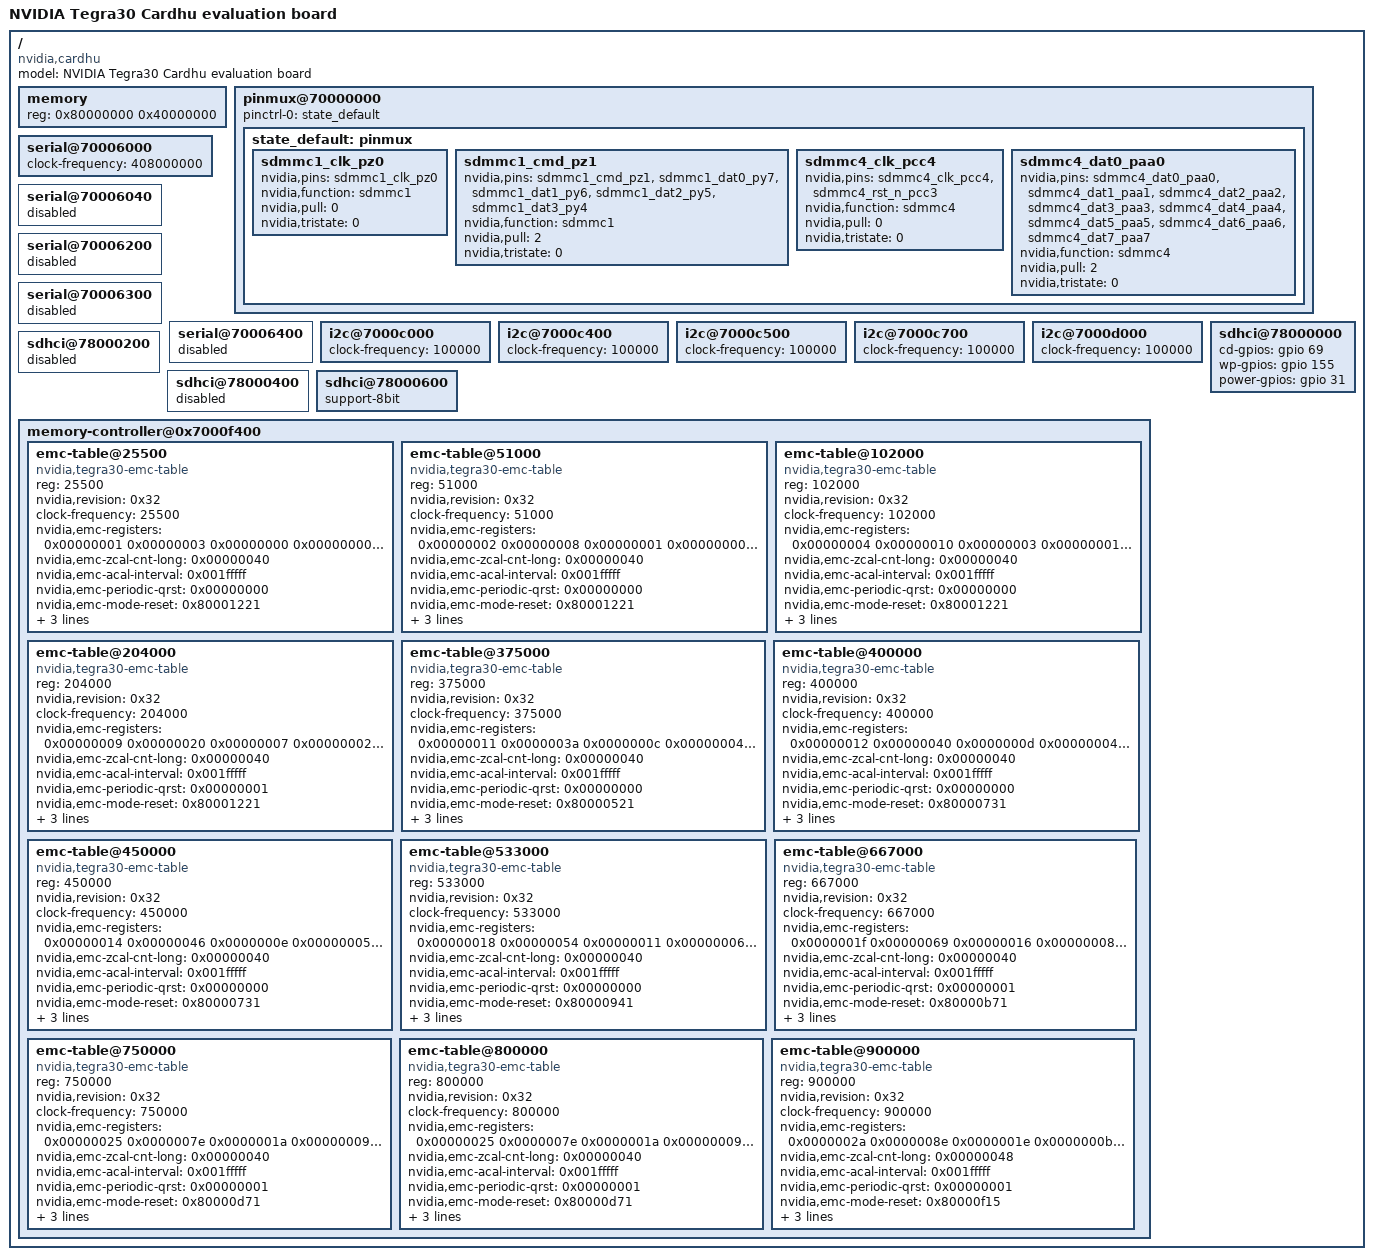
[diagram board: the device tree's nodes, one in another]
/dts-v1/;

/include/ "tegra30.dtsi"

/ {
	model = "NVIDIA Tegra30 Cardhu evaluation board";
	compatible = "nvidia,cardhu", "nvidia,tegra30";

	memory {
		reg = < 0x80000000 0x40000000 >;
	};

	pinmux@70000000 {
		pinctrl-names = "default";
		pinctrl-0 = <&state_default>;

		state_default: pinmux {
			sdmmc1_clk_pz0 {
				nvidia,pins = "sdmmc1_clk_pz0";
				nvidia,function = "sdmmc1";
				nvidia,pull = <0>;
				nvidia,tristate = <0>;
			};
			sdmmc1_cmd_pz1 {
				nvidia,pins =	"sdmmc1_cmd_pz1",
						"sdmmc1_dat0_py7",
						"sdmmc1_dat1_py6",
						"sdmmc1_dat2_py5",
						"sdmmc1_dat3_py4";
				nvidia,function = "sdmmc1";
				nvidia,pull = <2>;
				nvidia,tristate = <0>;
			};
			sdmmc4_clk_pcc4 {
				nvidia,pins =	"sdmmc4_clk_pcc4",
						"sdmmc4_rst_n_pcc3";
				nvidia,function = "sdmmc4";
				nvidia,pull = <0>;
				nvidia,tristate = <0>;
			};
			sdmmc4_dat0_paa0 {
				nvidia,pins =	"sdmmc4_dat0_paa0",
						"sdmmc4_dat1_paa1",
						"sdmmc4_dat2_paa2",
						"sdmmc4_dat3_paa3",
						"sdmmc4_dat4_paa4",
						"sdmmc4_dat5_paa5",
						"sdmmc4_dat6_paa6",
						"sdmmc4_dat7_paa7";
				nvidia,function = "sdmmc4";
				nvidia,pull = <2>;
				nvidia,tristate = <0>;
			};
		};
	};

	serial@70006000 {
		clock-frequency = < 408000000 >;
	};

	serial@70006040 {
		status = "disable";
	};

	serial@70006200 {
		status = "disable";
	};

	serial@70006300 {
		status = "disable";
	};

	serial@70006400 {
		status = "disable";
	};

	i2c@7000c000 {
		clock-frequency = <100000>;
	};

	i2c@7000c400 {
		clock-frequency = <100000>;
	};

	i2c@7000c500 {
		clock-frequency = <100000>;
	};

	i2c@7000c700 {
		clock-frequency = <100000>;
	};

	i2c@7000d000 {
		clock-frequency = <100000>;
	};

	sdhci@78000000 {
		cd-gpios = <&gpio 69 0>; /* gpio PI5 */
		wp-gpios = <&gpio 155 0>; /* gpio PT3 */
		power-gpios = <&gpio 31 0>; /* gpio PD7 */
	};

	sdhci@78000200 {
		status = "disable";
	};

	sdhci@78000400 {
		status = "disable";
	};

	sdhci@78000600 {
		support-8bit;
	};

	memory-controller@0x7000f400 {
		emc-table@25500 {
			compatible = "nvidia,tegra30-emc-table";
			reg = <25500>;
			nvidia,revision = <0x32>;
			clock-frequency = <25500>;
			nvidia,emc-registers = <0x00000001 0x00000003
					0x00000000 0x00000000 0x00000002 0x0000000a 0x00000003 0x0000000b 0x00000000
					0x00000000 0x00000003 0x00000001 0x00000000 0x00000005 0x00000005 0x00000004
					0x00000007 0x0000000c 0x000000bd 0x00000000 0x0000002f 0x00000002 0x00000002
					0x00000001 0x00000000 0x00000007 0x0000000f 0x00000005 0x00000005 0x00000004
					0x00000001 0x00000000 0x00000004 0x00000005 0x000000c3 0x00000000 0x00000004
					0x00000000 0x00000000 0x00006288 0x007800a4 0x00008000 0x00080000 0x00080000
					0x00080000 0x00080000 0x00080000 0x00080000 0x00080000 0x00080000 0x00000000
					0x00000000 0x00000000 0x00000000 0x00000000 0x00000000 0x00000000 0x00000000
					0x00000000 0x00000000 0x00000000 0x00000000 0x00000000 0x00000000 0x00000000
					0x00000000 0x00080000 0x00080000 0x00080000 0x00080000 0x000002a0 0x0800211c
					0x00000000 0x77ffc084 0x01f1f108 0x05057404 0x54000007 0x08000168 0x08000000
					0x00000802 0x00000000 0x00000040 0x000c000c 0xa0f10000 0x00000000 0x00000000
					0x80000280 0x00020001 0xc0000010 0x00000001 0x00000001 0x00000002 0x00000000
					0x00000001 0x00000001 0x00000002 0x00000008 0x00000002 0x00000001 0x00000002
					0x00000006 0x06020102 0x000a0402 0x74430303 0x001f0000 0xd8000000 0xff00ff00>;
			nvidia,emc-zcal-cnt-long = <0x00000040>;
			nvidia,emc-acal-interval = <0x001fffff>;
			nvidia,emc-periodic-qrst = <0x00000000>;
			nvidia,emc-mode-reset = <0x80001221>;
			nvidia,emc-mode-1 = <0x80100003>;
			nvidia,emc-mode-2 = <0x80200008>;
			nvidia,emc-dsr = <0x00000001>;
		};

		emc-table@51000 {
			compatible = "nvidia,tegra30-emc-table";
			reg = <51000>;
			nvidia,revision = <0x32>;
			clock-frequency = <51000>;
			nvidia,emc-registers = < 0x00000002 0x00000008
					0x00000001 0x00000000 0x00000002 0x0000000a 0x00000003 0x0000000b 0x00000000
					0x00000000 0x00000003 0x00000001 0x00000000 0x00000005 0x00000005 0x00000004
					0x00000007 0x0000000c 0x00000181 0x00000000 0x00000060 0x00000002 0x00000002
					0x00000001 0x00000000 0x00000007 0x0000000f 0x00000009 0x00000009 0x00000004
					0x00000002 0x00000000 0x00000004 0x00000005 0x0000018e 0x00000000 0x00000004
					0x00000000 0x00000000 0x00006288 0x007800a4 0x00008000 0x00080000 0x00080000
					0x00080000 0x00080000 0x00080000 0x00080000 0x00080000 0x00080000 0x00000000
					0x00000000 0x00000000 0x00000000 0x00000000 0x00000000 0x00000000 0x00000000
					0x00000000 0x00000000 0x00000000 0x00000000 0x00000000 0x00000000 0x00000000
					0x00000000 0x00080000 0x00080000 0x00080000 0x00080000 0x000002a0 0x0800211c
					0x00000000 0x77ffc084 0x01f1f108 0x05057404 0x54000007 0x08000168 0x08000000
					0x00000802 0x00000000 0x00000040 0x000c000c 0xa0f10000 0x00000000 0x00000000
					0x8000040b 0x00000001 0xc0000010 0x00000001 0x00000001 0x00000002 0x00000000
					0x00000001 0x00000001 0x00000002 0x00000008 0x00000002 0x00000001 0x00000002
					0x00000006 0x06020102 0x000a0402 0x73430303 0x001f0000 0xd8000000 0xff00ff00>;
			nvidia,emc-zcal-cnt-long = <0x00000040>;
			nvidia,emc-acal-interval = <0x001fffff>;
			nvidia,emc-periodic-qrst = <0x00000000>;
			nvidia,emc-mode-reset = <0x80001221>;
			nvidia,emc-mode-1 = <0x80100003>;
			nvidia,emc-mode-2 = <0x80200008>;
			nvidia,emc-dsr = <0x00000001>;
		};

		emc-table@102000 {
			compatible = "nvidia,tegra30-emc-table";
			reg = <102000>;
			nvidia,revision = <0x32>;
			clock-frequency = <102000>;
			nvidia,emc-registers = <0x00000004 0x00000010
					0x00000003 0x00000001 0x00000002 0x0000000a 0x00000003 0x0000000b 0x00000001
					0x00000001 0x00000003 0x00000001 0x00000000 0x00000005 0x00000005 0x00000004
					0x00000007 0x0000000c 0x00000303 0x00000000 0x000000c0 0x00000002 0x00000002
					0x00000001 0x00000000 0x00000007 0x0000000f 0x00000012 0x00000012 0x00000004
					0x00000004 0x00000000 0x00000004 0x00000005 0x0000031c 0x00000000 0x00000004
					0x00000000 0x00000000 0x00006288 0x007800a4 0x00008000 0x00080000 0x00080000
					0x00080000 0x00080000 0x00080000 0x00080000 0x00080000 0x00080000 0x00000000
					0x00000000 0x00000000 0x00000000 0x00000000 0x00000000 0x00000000 0x00000000
					0x00000000 0x00000000 0x00000000 0x00000000 0x00000000 0x00000000 0x00000000
					0x00000000 0x00080000 0x00080000 0x00080000 0x00080000 0x000002a0 0x0800211c
					0x00000000 0x77ffc084 0x01f1f108 0x05057404 0x54000007 0x08000168 0x08000000
					0x00000802 0x00000000 0x00000040 0x000c000c 0xa0f10000 0x00000000 0x00000000
					0x80000713 0x00000001 0xc0000018 0x00000001 0x00000001 0x00000003 0x00000000
					0x00000001 0x00000001 0x00000002 0x00000008 0x00000002 0x00000001 0x00000002
					0x00000006 0x06020102 0x000a0403 0x72830504 0x001f0000 0xd8000000 0xff00ff00>;
			nvidia,emc-zcal-cnt-long = <0x00000040>;
			nvidia,emc-acal-interval = <0x001fffff>;
			nvidia,emc-periodic-qrst = <0x00000000>;
			nvidia,emc-mode-reset = <0x80001221>;
			nvidia,emc-mode-1 = <0x80100003>;
			nvidia,emc-mode-2 = <0x80200008>;
			nvidia,emc-dsr = <0x00000001>;
		};

		emc-table@204000 {
			compatible = "nvidia,tegra30-emc-table";
			reg = <204000>;
			nvidia,revision = <0x32>;
			clock-frequency = <204000>;
			nvidia,emc-registers = <0x00000009 0x00000020
					0x00000007 0x00000002 0x00000002 0x0000000a 0x00000005 0x0000000b 0x00000002
					0x00000002 0x00000003 0x00000001 0x00000000 0x00000005 0x00000005 0x00000004
					0x00000009 0x0000000b 0x00000607 0x00000000 0x00000181 0x00000002 0x00000002
					0x00000001 0x00000000 0x00000007 0x0000000f 0x00000023 0x00000023 0x00000004
					0x00000007 0x00000000 0x00000004 0x00000005 0x00000638 0x00000006 0x00000004
					0x00000000 0x00000000 0x00004288 0x004400a4 0x00008000 0x00080000 0x00080000
					0x00080000 0x00080000 0x00080000 0x00080000 0x00080000 0x00080000 0x00000000
					0x00000000 0x00000000 0x00000000 0x00000000 0x00000000 0x00000000 0x00000000
					0x00000000 0x00000000 0x00000000 0x00000000 0x00000000 0x00000000 0x00000000
					0x00000000 0x00080000 0x00080000 0x00080000 0x00080000 0x000002a0 0x0800211c
					0x00000000 0x77fff884 0x01f1f108 0x05057404 0x54000007 0x08000168 0x08000000
					0x00000802 0x00020000 0x00000100 0x000c000c 0xa0f10000 0x00000000 0x00000000
					0x80000d22 0x00000003 0xc0000025 0x00000001 0x00000001 0x00000005 0x00000002
					0x00000003 0x00000001 0x00000003 0x00000008 0x00000002 0x00000001 0x00000002
					0x00000006 0x06020102 0x000a0505 0x72440a06 0x001f0000 0xe8000000 0xff00ff00>;
			nvidia,emc-zcal-cnt-long = <0x00000040>;
			nvidia,emc-acal-interval = <0x001fffff>;
			nvidia,emc-periodic-qrst = <0x00000001>;
			nvidia,emc-mode-reset = <0x80001221>;
			nvidia,emc-mode-1 = <0x80100003>;
			nvidia,emc-mode-2 = <0x80200008>;
			nvidia,emc-dsr = <0x00000001>;
		};

		emc-table@375000 {
			compatible = "nvidia,tegra30-emc-table";
			reg = <375000>;
			nvidia,revision = <0x32>;
			clock-frequency = <375000>;
			nvidia,emc-registers = <0x00000011 0x0000003a
					0x0000000c 0x00000004 0x00000003 0x00000008 0x00000002 0x0000000a 0x00000004
					0x00000004 0x00000002 0x00000001 0x00000000 0x00000004 0x00000006 0x00000004
					0x00000008 0x0000000d 0x00000b2d 0x00000000 0x000002cb 0x00000008 0x00000008
					0x00000001 0x00000000 0x00000007 0x0000000f 0x00000040 0x00000200 0x00000009
					0x0000000c 0x00000000 0x00000004 0x00000005 0x00000b6d 0x00000000 0x00000006
					0x00000000 0x00000000 0x00007088 0x00200084 0x00008000 0x0003c000 0x0003c000
					0x0003c000 0x0003c000 0x0003c000 0x0003c000 0x0003c000 0x0003c000 0x00000000
					0x00000000 0x00000000 0x00000000 0x00000000 0x00000000 0x00000000 0x00000000
					0x00000000 0x00000000 0x00000000 0x00000000 0x00000000 0x00000000 0x00000000
					0x00000000 0x00040000 0x00040000 0x00040000 0x00040000 0x000002a0 0x0800013d
					0x00000000 0x77fff884 0x01f1f508 0x05057404 0x54000007 0x080001e8 0x08000021
					0x00000802 0x00020000 0x00000100 0x0184000c 0xa0f10000 0x00000000 0x00000000
					0x8000174b 0x00000005 0x80000044 0x00000001 0x00000002 0x00000009 0x00000005
					0x00000005 0x00000001 0x00000002 0x00000008 0x00000002 0x00000002 0x00000003
					0x00000006 0x06030202 0x000d0709 0x75c6110a 0x001f0000 0x58000000 0xff00ff88>;
			nvidia,emc-zcal-cnt-long = <0x00000040>;
			nvidia,emc-acal-interval = <0x001fffff>;
			nvidia,emc-periodic-qrst = <0x00000000>;
			nvidia,emc-mode-reset = <0x80000521>;
			nvidia,emc-mode-1 = <0x80100002>;
			nvidia,emc-mode-2 = <0x80200000>;
			nvidia,emc-dsr = <0x00000000>;
		};

		emc-table@400000 {
			compatible = "nvidia,tegra30-emc-table";
			reg = <400000>;
			nvidia,revision = <0x32>;
			clock-frequency = <400000>;
			nvidia,emc-registers = <0x00000012 0x00000040
					0x0000000d 0x00000004 0x00000002 0x00000009 0x00000002 0x0000000c 0x00000004
					0x00000004 0x00000002 0x00000001 0x00000000 0x00000005 0x00000007 0x00000005
					0x00000008 0x0000000e 0x00000c2e 0x00000000 0x0000030b 0x00000008 0x00000008
					0x00000001 0x00000000 0x00000008 0x00000011 0x00000046 0x00000200 0x0000000a
					0x0000000d 0x00000000 0x00000004 0x00000005 0x00000c6f 0x00000000 0x00000006
					0x00000000 0x00000000 0x00007088 0x001c0084 0x00008000 0x00034000 0x00034000
					0x00034000 0x00034000 0x00034000 0x00034000 0x00034000 0x00034000 0x00000000
					0x00000000 0x00000000 0x00000000 0x00000000 0x00000000 0x00000000 0x00000000
					0x00000000 0x00000000 0x00000000 0x00000000 0x00000000 0x00000000 0x00000000
					0x00000000 0x00040000 0x00040000 0x00040000 0x00040000 0x000002a0 0x0800013d
					0x00000000 0x77fff884 0x01f1f508 0x05057404 0x54000007 0x080001e8 0x08000021
					0x00000802 0x00020000 0x00000100 0x017f000c 0xa0f10000 0x00000000 0x00000000
					0x80001941 0x00000006 0x8000004a 0x00000001 0x00000002 0x0000000a 0x00000006
					0x00000006 0x00000001 0x00000002 0x00000009 0x00000002 0x00000002 0x00000003
					0x00000006 0x06030202 0x000e070a 0x7547130b 0x001f0000 0x58000000 0xff00ff88>;
			nvidia,emc-zcal-cnt-long = <0x00000040>;
			nvidia,emc-acal-interval = <0x001fffff>;
			nvidia,emc-periodic-qrst = <0x00000000>;
			nvidia,emc-mode-reset = <0x80000731>;
			nvidia,emc-mode-1 = <0x80100002>;
			nvidia,emc-mode-2 = <0x80200008>;
			nvidia,emc-dsr = <0x00000000>;
		};

		emc-table@450000 {
			compatible = "nvidia,tegra30-emc-table";
			reg = <450000>;
			nvidia,revision = <0x32>;
			clock-frequency = <450000>;
			nvidia,emc-registers = <0x00000014 0x00000046
					0x0000000e 0x00000005 0x00000003 0x00000009 0x00000002 0x0000000c 0x00000005
					0x00000005 0x00000002 0x00000001 0x00000000 0x00000005 0x00000007 0x00000005
					0x0000000a 0x0000000e 0x00000d76 0x00000000 0x0000035d 0x00000001 0x00000009
					0x00000001 0x00000000 0x00000009 0x00000011 0x0000004d 0x00000200 0x00000004
					0x0000000e 0x00000000 0x00000004 0x00000005 0x00000db6 0x00000000 0x00000006
					0x00000000 0x00000000 0x00007088 0x00180084 0x00008000 0x00022000 0x00022000
					0x00022000 0x00022000 0x00022000 0x00022000 0x00022000 0x00022000 0x00000000
					0x00000000 0x00000000 0x00000000 0x00000000 0x00000000 0x00000000 0x00000000
					0x00000000 0x00000000 0x00000000 0x00000000 0x00000000 0x00000000 0x00000000
					0x00000000 0x00030000 0x00030000 0x00030000 0x00030000 0x000002a0 0x0800013d
					0x00000000 0x77fff884 0x01f1f508 0x05057404 0x54000007 0x080001e8 0x08000021
					0x00000802 0x00020000 0x00000100 0x0178000c 0xa0f10000 0x00000000 0x00000000
					0x80001bc0 0x00000006 0x80000051 0x00000002 0x00000003 0x0000000b 0x00000006
					0x00000006 0x00000001 0x00000002 0x00000009 0x00000002 0x00000002 0x00000003
					0x00000006 0x06030202 0x000f080b 0x70a7150c 0x001f0000 0xe8000000 0xff00ff8b>;
			nvidia,emc-zcal-cnt-long = <0x00000040>;
			nvidia,emc-acal-interval = <0x001fffff>;
			nvidia,emc-periodic-qrst = <0x00000000>;
			nvidia,emc-mode-reset = <0x80000731>;
			nvidia,emc-mode-1 = <0x80100002>;
			nvidia,emc-mode-2 = <0x80200008>;
			nvidia,emc-dsr = <0x00000000>;
		};

		emc-table@533000 {
			compatible = "nvidia,tegra30-emc-table";
			reg = <533000>;
			nvidia,revision = <0x32>;
			clock-frequency = <533000>;
			nvidia,emc-registers = <0x00000018 0x00000054
					0x00000011 0x00000006 0x00000003 0x00000009 0x00000002 0x0000000d 0x00000006
					0x00000006 0x00000002 0x00000001 0x00000000 0x00000005 0x00000008 0x00000006
					0x00000008 0x00000010 0x00000ffd 0x00000000 0x000003ff 0x0000000b 0x0000000b
					0x00000001 0x00000000 0x0000000a 0x00000012 0x0000005b 0x00000200 0x0000000d
					0x00000010 0x00000000 0x00000005 0x00000006 0x0000103e 0x00000000 0x00000006
					0x00000000 0x00000000 0x00007088 0x00120084 0x00008000 0x00010000 0x00010000
					0x00010000 0x00010000 0x00010000 0x00010000 0x00010000 0x00010000 0x00000000
					0x00000000 0x00000000 0x00000000 0x00000000 0x00000000 0x00000000 0x00000000
					0x00000000 0x00000000 0x00000000 0x00000000 0x00000000 0x00000000 0x00000000
					0x00000000 0x00020000 0x00020000 0x00020000 0x00020000 0x000006a0 0x0800013d
					0x00000000 0x77ffc084 0x01f1f508 0x05057404 0x54000007 0x08000168 0x08000021
					0x00000802 0x00000000 0x00000040 0x01ab000c 0xa0f10404 0x00000000 0x00000000
					0x800020ae 0x00000008 0x80000060 0x00000002 0x00000003 0x0000000d 0x00000008
					0x00000007 0x00000001 0x00000002 0x00000009 0x00000002 0x00000002 0x00000003
					0x00000006 0x06030202 0x0010090d 0x7028180e 0x001f0000 0x00000000 0xff00ff00>;
			nvidia,emc-zcal-cnt-long = <0x00000040>;
			nvidia,emc-acal-interval = <0x001fffff>;
			nvidia,emc-periodic-qrst = <0x00000000>;
			nvidia,emc-mode-reset = <0x80000941>;
			nvidia,emc-mode-1 = <0x80100002>;
			nvidia,emc-mode-2 = <0x80200008>;
			nvidia,emc-dsr = <0x00000000>;
		};

		emc-table@667000 {
			compatible = "nvidia,tegra30-emc-table";
			reg = <667000>;
			nvidia,revision = <0x32>;
			clock-frequency = <667000>;
			nvidia,emc-registers = <0x0000001f 0x00000069
					0x00000016 0x00000008 0x00000004 0x0000000c 0x00000003 0x00000011 0x00000008
					0x00000008 0x00000002 0x00000001 0x00000000 0x00000007 0x0000000b 0x00000009
					0x0000000c 0x00000011 0x00001412 0x00000000 0x00000504 0x0000000e 0x0000000e
					0x00000001 0x00000000 0x0000000c 0x00000016 0x00000072 0x00000200 0x00000010
					0x00000015 0x00000000 0x00000006 0x00000007 0x00001453 0x0000000c 0x00000004
					0x00000000 0x00000000 0x00005088 0x40070191 0x00008000 0x00000008 0x00000008
					0x00000008 0x00000008 0x00000008 0x00000008 0x00000008 0x00000008 0x00000000
					0x00000000 0x00000000 0x00000000 0x00000000 0x00000000 0x00000000 0x00000000
					0x00000000 0x00000000 0x00000000 0x00000000 0x00000000 0x00000000 0x00000000
					0x00000000 0x00000008 0x00000008 0x00000008 0x00000008 0x000002a0 0x0600013d
					0x00000000 0x77fff884 0x01f1f508 0x07077404 0x54000000 0x080001e8 0x07000021
					0x00000802 0x00020000 0x00000100 0x01d6000c 0xa0f10000 0x00000000 0x00000000
					0x800028a5 0x0000000a 0x80000079 0x00000003 0x00000004 0x00000010 0x0000000a
					0x0000000a 0x00000001 0x00000003 0x0000000b 0x00000002 0x00000002 0x00000004
					0x00000008 0x08040202 0x00140c10 0x734a1f11 0x001f0000 0xf8000000 0xff00ff01>;
			nvidia,emc-zcal-cnt-long = <0x00000040>;
			nvidia,emc-acal-interval = <0x001fffff>;
			nvidia,emc-periodic-qrst = <0x00000001>;
			nvidia,emc-mode-reset = <0x80000b71>;
			nvidia,emc-mode-1 = <0x80100002>;
			nvidia,emc-mode-2 = <0x80200018>;
			nvidia,emc-dsr = <0x00000000>;
		};

		emc-table@750000 {
			compatible = "nvidia,tegra30-emc-table";
			reg = <750000>;
			nvidia,revision = <0x32>;
			clock-frequency = <750000>;
			nvidia,emc-registers = <0x00000025 0x0000007e
					0x0000001a 0x00000009 0x00000004 0x0000000d 0x00000004 0x00000013 0x00000009
					0x00000009 0x00000003 0x00000001 0x00000000 0x00000007 0x0000000b 0x00000009
					0x0000000c 0x00000011 0x0000169a 0x00000000 0x00000608 0x00000012 0x00000012
					0x00000001 0x00000000 0x0000000f 0x00000018 0x00000088 0x00000200 0x00000014
					0x00000018 0x00000000 0x00000007 0x00000008 0x00001860 0x0000000c 0x00000004
					0x00000000 0x00000000 0x00005088 0xf0080191 0x00008000 0x00000008 0x00000008
					0x00000008 0x00000008 0x00000008 0x00000008 0x00000008 0x00000008 0x00000000
					0x00000000 0x00000000 0x00000000 0x00000000 0x00000000 0x00000000 0x00000000
					0x00000000 0x00000000 0x00000000 0x00000000 0x00000000 0x00000000 0x00000000
					0x00000000 0x0000000c 0x0000000c 0x0000000c 0x0000000c 0x000002a0 0x0600013d
					0x22220000 0x77fff884 0x01f1f501 0x07077404 0x54000000 0x080001e8 0x07000021
					0x00000802 0x00020000 0x00000100 0x0180000c 0xa0f10000 0x00000000 0x00000000
					0x8000308c 0x0000000c 0x80000090 0x00000004 0x00000005 0x00000013 0x0000000c
					0x0000000b 0x00000002 0x00000003 0x0000000c 0x00000002 0x00000002 0x00000004
					0x00000008 0x08040202 0x00160d13 0x72ac2414 0x001f0000 0xf8000000 0xff00ff49>;
			nvidia,emc-zcal-cnt-long = <0x00000040>;
			nvidia,emc-acal-interval = <0x001fffff>;
			nvidia,emc-periodic-qrst = <0x00000001>;
			nvidia,emc-mode-reset = <0x80000d71>;
			nvidia,emc-mode-1 = <0x80100002>;
			nvidia,emc-mode-2 = <0x80200018>;
			nvidia,emc-dsr = <0x00000000>;
		};

		emc-table@800000 {
			compatible = "nvidia,tegra30-emc-table";
			reg = <800000>;
			nvidia,revision = <0x32>;
			clock-frequency = <800000>;
			nvidia,emc-registers = <0x00000025 0x0000007e
					0x0000001a 0x00000009 0x00000004 0x0000000d 0x00000004 0x00000013 0x00000009
					0x00000009 0x00000003 0x00000001 0x00000000 0x00000007 0x0000000b 0x00000009
					0x0000000c 0x00000011 0x00001820 0x00000000 0x00000608 0x00000012 0x00000012
					0x00000001 0x00000000 0x0000000f 0x00000018 0x00000088 0x00000200 0x00000014
					0x00000018 0x00000000 0x00000007 0x00000008 0x00001860 0x0000000c 0x00000004
					0x00000000 0x00000000 0x00005088 0xf0070191 0x00008000 0x0000800a 0x0000000a
					0x0000000a 0x0000000a 0x0000000a 0x0000000a 0x0000000a 0x0000000a 0x00000000
					0x00000000 0x00000000 0x00000000 0x00000000 0x00000000 0x00000000 0x00000000
					0x00000000 0x00000000 0x00000000 0x00000000 0x00000000 0x00000000 0x00000000
					0x00000000 0x007fc00a 0x0000000a 0x0000000a 0x0000000a 0x000002a0 0x0600013d
					0x22220000 0x77fff884 0x01f1f501 0x07077404 0x54000000 0x080001e8 0x07000021
					0x00000802 0x00020000 0x00000100 0x0180000c 0xa0f10000 0x00000000 0x00000000
					0x8000308c 0x0000000c 0x80000090 0x00000004 0x00000005 0x00000013 0x0000000c
					0x0000000b 0x00000002 0x00000003 0x0000000c 0x00000002 0x00000002 0x00000004
					0x00000008 0x08040202 0x00160d13 0x72ac2414 0x001f0000 0xf8000000 0xff00ff49>;
			nvidia,emc-zcal-cnt-long = <0x00000040>;
			nvidia,emc-acal-interval = <0x001fffff>;
			nvidia,emc-periodic-qrst = <0x00000001>;
			nvidia,emc-mode-reset = <0x80000d71>;
			nvidia,emc-mode-1 = <0x80100002>;
			nvidia,emc-mode-2 = <0x80200018>;
			nvidia,emc-dsr = <0x00000000>;
		};

		emc-table@900000 {
			compatible = "nvidia,tegra30-emc-table";
			reg = <900000>;
			nvidia,revision = <0x32>;
			clock-frequency = <900000>;
			nvidia,emc-registers = <0x0000002a 0x0000008e
					0x0000001e 0x0000000b 0x00000006 0x0000000f 0x00000005 0x00000016 0x0000000b
					0x0000000b 0x00000004 0x00000001 0x00000000 0x00000008 0x0000000d 0x0000000b
					0x0000000b 0x00000014 0x00001b2c 0x00000000 0x000006cb 0x00000004 0x00000014
					0x00000001 0x00000000 0x00000011 0x0000001b 0x00000099 0x00000200 0x00000006
					0x0000001b 0x00000000 0x00000008 0x00000009 0x00001b6c 0x0000000e 0x00000004
					0x00000000 0x00000000 0x00005088 0xf0040191 0x00008000 0x0000800a 0x0000000a
					0x007fc00a 0x0000000a 0x0000000a 0x0000000a 0x0000000a 0x0000000a 0x0001c000
					0x0001c000 0x0001c000 0x0001c000 0x0001c000 0x0001c000 0x0001c000 0x0001c000
					0x00000000 0x00000000 0x00000000 0x00000000 0x00000000 0x00000000 0x00000000
					0x00000000 0x007fc00a 0x0000000a 0x0000000a 0x0000000a 0x000002a0 0x0600013d
					0x22220000 0x77fff884 0x01f1f501 0x07077404 0x54000000 0x080001e8 0x07000021
					0x00000802 0x00020000 0x00000120 0x0128000c 0xa0f10000 0x00000000 0x00000000
					0x8000367d 0x0000000d 0x800000a2 0x00000005 0x00000006 0x00000016 0x0000000e
					0x0000000d 0x00000002 0x00000004 0x0000000e 0x00000002 0x00000002 0x00000005
					0x00000009 0x09050202 0x001a1016 0x714e2917 0x001f0000 0xe8000000 0xff00ff4b>;
			nvidia,emc-zcal-cnt-long = <0x00000048>;
			nvidia,emc-acal-interval = <0x001fffff>;
			nvidia,emc-periodic-qrst = <0x00000001>;
			nvidia,emc-mode-reset = <0x80000f15>;
			nvidia,emc-mode-1 = <0x80100002>;
			nvidia,emc-mode-2 = <0x80200020>;
			nvidia,emc-dsr = <0x00000000>;
		};

	};
};
